# ATtiny828 device description
Architecture: AVR8; Family: tinyAVR
Registers are 8-bit, access not given, no defined reset value unless marked. A register's access mark holds for its fields unless they carry their own. Offsets are from the block's base; [hi:lo] are bit positions.

## LOCKBIT — Lockbits
Instances: LOCKBIT 0 in lockbits
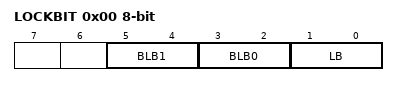
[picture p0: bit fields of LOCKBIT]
0x00 LOCKBIT
  [5:4] BLB1 — Boot Loader Protection Mode
    0=LPM_SPM_DISABLE (LPM and SPM prohibited in Boot Section); 1=LPM_DISABLE (LPM prohibited in Boot Section); 2=SPM_DISABLE (SPM prohibited in Boot Section); 3=NO_LOCK (No lock on SPM and LPM in Boot Section)
  [3:2] BLB0 — Boot Loader Protection Mode
    0=LPM_SPM_DISABLE (LPM and SPM prohibited in Application Section); 1=LPM_DISABLE (LPM prohibited in Application Section); 2=SPM_DISABLE (SPM prohibited in Application Section); 3=NO_LOCK (No lock on SPM and LPM in Application Section)
  [1:0] LB — Memory Lock
    0=PROG_VER_DISABLED (Further programming and verification disabled); 2=PROG_DISABLED (Further programming disabled); 3=NO_LOCK (No memory lock features enabled)

## SPI — Serial Peripheral Interface
Instances: SPI 0x00
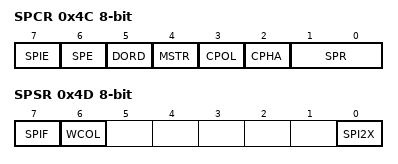
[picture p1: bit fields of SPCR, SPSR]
0x4C SPCR — SPI Control Register
  [7] SPIE — SPI Interrupt Enable
  [6] SPE — SPI Enable
  [5] DORD — Data Order
  [4] MSTR — Master/Slave Select
  [3] CPOL — Clock polarity
  [2] CPHA — Clock Phase
  [1:0] SPR — SPI Clock Rate Selects
    0=fosc/4; 1=fosc/16; 2=fosc/64; 3=fosc/128; 4=fosc/2; 5=fosc/8; 6=fosc/32; 7=fosc/64
0x4D SPSR — SPI Status Register
  [7] SPIF — SPI Interrupt Flag
  [6] WCOL — Write Collision Flag
  [0] SPI2X — Double SPI Speed Bit
0x4E SPDR — SPI Data Register

## PORTA — I/O Port
Instances: PORTA 0x00
0x20 PINA — Port A Input Pins
0x21 DDRA — Data Direction Register, Port A
0x22 PORTA — Port A Data Register
0x23 PUEA — Pull-up Enable Control Register

## PORTB — I/O Port
Instances: PORTB 0x00
0x24 PINB — Port B Input Pins
0x25 DDRB — Data Direction Register, Port B
0x26 PORTB — Port B Data Register
0x27 PUEB — Pull-up Enable Control Register

## PORTC — I/O Port
Instances: PORTC 0x00
0x28 PINC — Port C Input Pins
0x29 DDRC — Data Direction Register, Port C
0x2A PORTC — Port C Data Register
0x2B PUEC — Pull-up Enable Control Register
0x34 PHDE — Port High Drive Enable Register
  [2] PHDEC — Port C High Drive Enable

## PORTD — I/O Port
Instances: PORTD 0x00
0x2C PIND bits used 3:0 — Port D Input Pins
0x2D DDRD bits used 3:0 — Data Direction Register, Port D
0x2E PORTD bits used 3:0 — Port D Data Register
0x2F PUED bits used 3:0 — Pull-up Enable Control Register

## CPU — CPU Registers
Instances: CPU 0x00
Parameters: CORE_VERSION=V2, NEW_INSTRUCTIONS=lpm rd,z+
0x3E GPIOR0 — General Purpose I/O Register 0
0x4A GPIOR1 — General Purpose I/O Register 1
0x4B GPIOR2 — General Purpose I/O Register 2
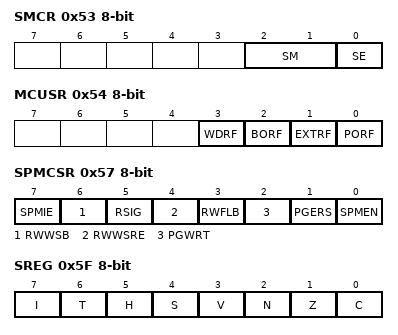
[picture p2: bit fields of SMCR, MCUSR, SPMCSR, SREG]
0x53 SMCR — Sleep Mode Control Register
  [2:1] SM — Sleep Mode Select Bits
    0=IDLE; 1=ADC (ADC Noise Reduction (If Available)); 2=PDOWN (Power Down)
  [0] SE — Sleep Enable
0x54 MCUSR — MCU Status Register
  [3] WDRF — Watchdog Reset Flag
  [2] BORF — Brown-out Reset Flag
  [1] EXTRF — External Reset Flag
  [0] PORF — Power-on reset flag
0x55 MCUCR — MCU Control Register
  [1] IVSEL — Interrupt Vector Select
0x56 CCP — Configuration Change Protection
0x57 SPMCSR — Store Program Memory Control and Status Register
  [7] SPMIE — SPM Interrupt Enable
  [6] RWWSB — Read-While-Write Section Busy
  [5] RSIG — Read Device Signature Imprint Table
  [4] RWWSRE — Read-While-Write section read enable
  [3] RWFLB — Read/Write Fuse and Lock Bits
  [2] PGWRT — Page Write
  [1] PGERS — Page Erase
  [0] SPMEN — Store Program Memory Enable
0x5D SP 16-bit bits used 9:0 — Stack Pointer
0x5F SREG — Status Register
  [7] I — Global Interrupt Enable
  [6] T — Bit Copy Storage
  [5] H — Half Carry Flag
  [4] S — Sign Bit
  [3] V — Two's Complement Overflow Flag
  [2] N — Negative Flag
  [1] Z — Zero Flag
  [0] C — Carry Flag
0x61 CLKPR — Clock Prescale Register
  [3:0] CLKPS — Clock Prescaler Select Bits
    0=1; 1=2; 2=4; 3=8; 4=16; 5=32; 6=64; 7=128; 8=256
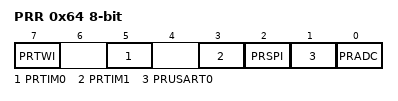
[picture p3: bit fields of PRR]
0x64 PRR — Power Reduction Register
  [7] PRTWI — Power Reduction TWI
  [5] PRTIM0 — Power Reduction Timer/Counter0
  [3] PRTIM1 — Power Reduction Timer/Counter1
  [2] PRSPI — Power Reduction SPI
  [1] PRUSART0 — Power Reduction USART 0
  [0] PRADC — Power Reduction ADC
0x66 OSCCAL0 — Oscillator Calibration Register 8MHz
0x67 OSCCAL1 bits used 1:0 — Oscillator Calibration Register 32kHz
0xF0 OSCTCAL0A — Oscillator Temperature Calibration Register A
0xF1 OSCTCAL0B — Oscillator Temperature Calibration Register B
Value list OSCCAL_VALUE_ADDRESSES: 0=8_0_MHz; 3=32_kHz
